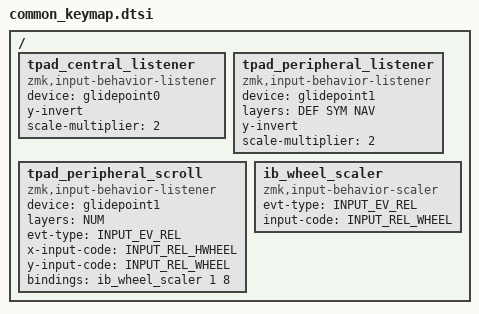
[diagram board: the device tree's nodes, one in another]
#include <behaviors.dtsi>
#include <dt-bindings/zmk/keys.h>
#include <dt-bindings/zmk/bt.h> 
#include <dt-bindings/zmk/rgb.h>
#include <dt-bindings/zmk/ext_power.h>
#include <dt-bindings/zmk/outputs.h>

#include <dt-bindings/zmk/mouse.h>
#include <behaviors/mouse_keys.dtsi>


#define DEF 0  // layer shortcuts, must match order in which they are defined below
#define NUM 1
#define SYM 2
#define NAV 3

#define MO_TO(layer) &mo_to layer layer   // Macro to apply momentary-layer-on-hold/to-layer-on-tap to a specific layer

/ {
	/* assign `input-listener` to all pointing devices */
	/* &glidepoint0 on central, &glidepoint1 on peripheral */
    tpad_central_listener {
        compatible = "zmk,input-behavior-listener";
        device = <&glidepoint0>;
        y-invert;
        scale-multiplier = <2>;
        // xy-swap;
        // x-invert;
	};

    tpad_peripheral_listener {
        compatible = "zmk,input-behavior-listener";
        device = <&glidepoint1>;
        layers = <DEF SYM NAV>;
        y-invert;
        scale-multiplier = <2>;
        /* NOTE: do NOT override event code here, */
        /*       let Cirque glidepoint reports click from taps */
        // evt-type = <INPUT_EV_REL>;
        // x-input-code = <INPUT_REL_X>;
        // y-input-code = <INPUT_REL_Y>;
    };

    tpad_peripheral_scroll {
        compatible = "zmk,input-behavior-listener";
        device = <&glidepoint1>;
        layers = <NUM>;
        /* NOTE: only apply input-code overriding for INPUT_EV_REL */
        evt-type = <INPUT_EV_REL>;
        x-input-code = <INPUT_REL_HWHEEL>;
        y-input-code = <INPUT_REL_WHEEL>;
        bindings = <&ib_wheel_scaler 1 8>;
    };

    ib_wheel_scaler: ib_wheel_scaler {
            compatible = "zmk,input-behavior-scaler";
            #binding-cells = <2>;
            evt-type = <INPUT_EV_REL>;
            input-code = <INPUT_REL_WHEEL>;
    };
};
